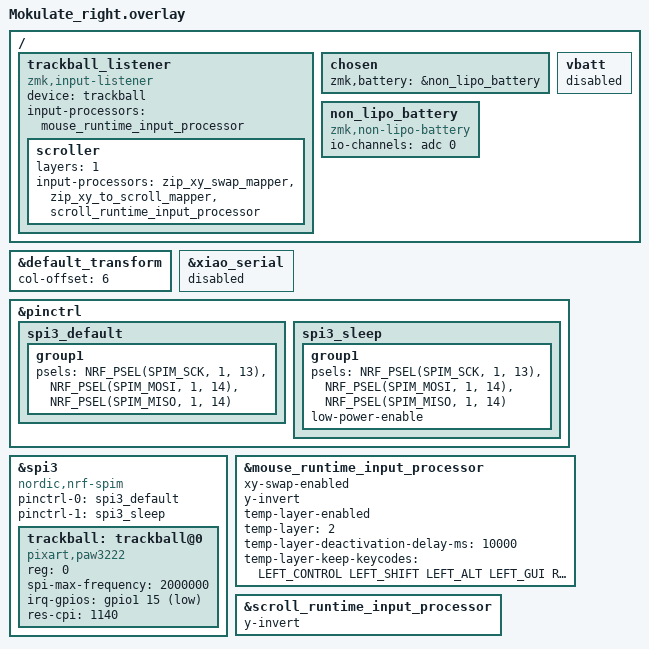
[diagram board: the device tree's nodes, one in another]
#include "Mokulate.dtsi"
#include <input/processors.dtsi>
#include <input/processors/runtime-input-processor.dtsi>
#include <behaviors/battery_history_request.dtsi>

// Right half is the peripheral. Shift charlieplex passive index by 6 so the
// transform map in Mokulate.dtsi covers both sides in one 6x12 grid.
&default_transform {
    col-offset = <6>;
};

&xiao_serial { status = "disabled"; };

// PAW3222 Trackball Configuration
// Wiring: CS=GND, MOTION=P1.15, SDIO=P1.14, SCLK=P1.13 (v2.1)
// Wiring: CS=GND, MOTION=P0.29, SDIO=P0.03, SCLK=P0.28 (v2.0)
// Wiring: CS=GND, MOTION=P0.10, SDIO=P0.09, SCLK=P1.11 (prototype)
&pinctrl {
    spi3_default: spi3_default {
        group1 {
            psels = <NRF_PSEL(SPIM_SCK, 1, 13)>,    /* P1.13 */
                    <NRF_PSEL(SPIM_MOSI, 1, 14)>,   /* P1.14 (SDIO: MOSI/MISO shorted) */
                    <NRF_PSEL(SPIM_MISO, 1, 14)>;   /* P1.14 */
        };
    };

    spi3_sleep: spi3_sleep {
        group1 {
            psels = <NRF_PSEL(SPIM_SCK, 1, 13)>,
                    <NRF_PSEL(SPIM_MOSI, 1, 14)>,
                    <NRF_PSEL(SPIM_MISO, 1, 14)>;
            low-power-enable;
        };
    };
};

&spi3 {
    status = "okay";
    compatible = "nordic,nrf-spim";
    pinctrl-0 = <&spi3_default>;
    pinctrl-1 = <&spi3_sleep>;
    pinctrl-names = "default", "sleep";


    trackball: trackball@0 {
        status = "okay";
        compatible = "pixart,paw3222";
        reg = <0>;
        spi-max-frequency = <2000000>;
        /* MOTION: P1.15 */
        irq-gpios = <&gpio1 15 (GPIO_ACTIVE_LOW | GPIO_PULL_UP)>;
        // PAW3222 CPI. Hardware default ~800 felt sluggish, 1900 felt too
        // high. RES_STEP=38, valid range 608..4826 (multiples of 38).
        res-cpi = <1140>;
    };
};

// Trackball runtime processor defaults (DYA Studio で上書き可能)
&mouse_runtime_input_processor {
    xy-swap-enabled;
    y-invert;
    temp-layer-enabled;
    temp-layer = <2>;
    temp-layer-deactivation-delay-ms = <10000>;
    // Auto Mouse Layer を解除しないキー（旧 excluded-positions 相当）
    temp-layer-keep-keycodes = <
        LEFT_CONTROL LEFT_SHIFT LEFT_ALT LEFT_GUI
        RIGHT_CONTROL RIGHT_SHIFT RIGHT_ALT RIGHT_GUI
        H J K L Z
    >;
};

&scroll_runtime_input_processor {
    y-invert;
};

// Trackball input listener (central side)
/ {
    trackball_listener: trackball_listener {
        compatible = "zmk,input-listener";
        device = <&trackball>;
        input-processors = <&mouse_runtime_input_processor>;

        scroller {
            layers = <1>;
            input-processors = <&zip_xy_swap_mapper &zip_xy_to_scroll_mapper &scroll_runtime_input_processor>;
        };
    };
};

/ {
    chosen {
        zmk,battery = &non_lipo_battery;
    };

    // Disable default Xiao BLE battery monitoring (uses AIN7 with voltage divider)
    vbatt: vbatt {
        status = "disabled";
    };

    // Non-LiPo battery on AIN0 (D0/P0.02) - direct connection, no voltage divider
    non_lipo_battery: non_lipo_battery {
        compatible = "zmk,non-lipo-battery";
        io-channels = <&adc 0>;
    };
};
